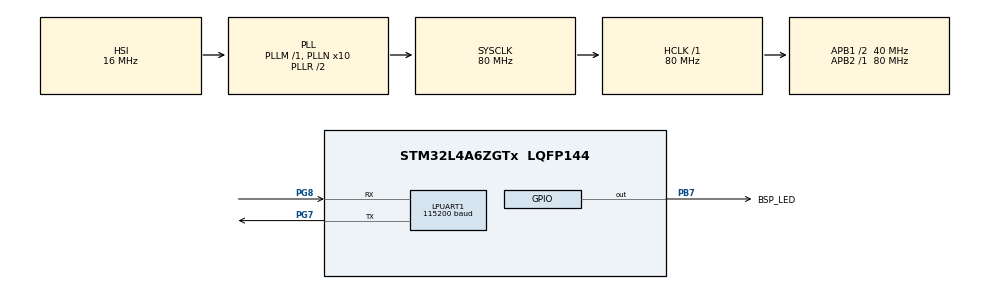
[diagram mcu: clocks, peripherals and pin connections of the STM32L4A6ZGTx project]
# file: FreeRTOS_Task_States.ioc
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FREERTOS.Tasks01=Default_Task,24,128,Start_Default_Task,Default,NULL,Dynamic,NULL,NULL;Task_2,8,128,Start_Task_2,Default,NULL,Dynamic,NULL,NULL
FREERTOS.configUSE_NEWLIB_REENTRANT=1
LPUART1.BaudRate=115200
LPUART1.WordLength=UART_WORDLENGTH_8B
Mcu.Family=STM32L4
Mcu.Name=STM32L4A6ZGTx
Mcu.Package=LQFP144
NVIC.PriorityGroup=NVIC_PRIORITYGROUP_4
NVIC.TIM6_DAC_IRQn=true\:15\:0\:false\:false\:true\:false\:false\:true\:true
NVIC.TimeBase=TIM6_DAC_IRQn
NVIC.TimeBaseIP=TIM6
PA13\ (JTMS/SWDIO).Mode=Serial_Wire
PA13\ (JTMS/SWDIO).Signal=SYS_JTMS-SWDIO
PA14\ (JTCK/SWCLK).Mode=Serial_Wire
PA14\ (JTCK/SWCLK).Signal=SYS_JTCK-SWCLK
PB7.GPIO_Label=BSP_LED
PB7.Signal=GPIO_Output
PG7.Mode=Asynchronous
PG7.Signal=LPUART1_TX
PG8.Mode=Asynchronous
PG8.Signal=LPUART1_RX
ProjectManager.HeapSize=0x200
ProjectManager.StackSize=0x400
ProjectManager.TargetToolchain=STM32CubeIDE
RCC.ADCFreq_Value=192000000
RCC.AHBFreq_Value=80000000
RCC.APB1CLKDivider=RCC_HCLK_DIV2
RCC.APB1Freq_Value=40000000
RCC.APB1TimFreq_Value=80000000
RCC.APB2Freq_Value=80000000
RCC.APB2TimFreq_Value=80000000
RCC.CortexFreq_Value=80000000
RCC.FLatency=FLASH_LATENCY_4
RCC.HCLKFreq_Value=80000000
RCC.HSE_VALUE=8000000
RCC.HSI48_VALUE=48000000
RCC.HSI_VALUE=16000000
RCC.MSI_VALUE=4000000
RCC.PLLN=10
RCC.PLLSAI1N=24
RCC.PLLSourceVirtual=RCC_PLLSOURCE_HSI
RCC.SYSCLKFreq_VALUE=80000000
RCC.SYSCLKSource=RCC_SYSCLKSOURCE_PLLCLK
RCC.USBFreq_Value=192000000
RCC.VCOOutputFreq_Value=160000000
VP_FREERTOS_VS_CMSIS_V2.Mode=CMSIS_V2
VP_SYS_VS_tim6.Mode=TIM6
board=NUCLEO-L4A6ZG

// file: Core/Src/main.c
/* USER CODE BEGIN Header */
/**
  ******************************************************************************
  * @file           : main.c
  * @brief          : Main program body
  ******************************************************************************
  * @attention
  *
  * Copyright (c) 2024 STMicroelectronics.
  * All rights reserved.
  *
  * This software is licensed under terms that can be found in the LICENSE file
  * in the root directory of this software component.
  * If no LICENSE file comes with this software, it is provided AS-IS.
  *
  ******************************************************************************
  */
/* USER CODE END Header */
#include "main.h"
#include "cmsis_os.h"

/* USER CODE BEGIN Includes */
#include <stdio.h>
/* USER CODE END Includes */

UART_HandleTypeDef hlpuart1;

/* Definitions for Default_Task */
osThreadId_t Default_TaskHandle;
const osThreadAttr_t Default_Task_attributes = {
  .name = "Default_Task",
  .stack_size = 128 * 4,
  .priority = (osPriority_t) osPriorityNormal,
};
/* Definitions for Task_2 */
osThreadId_t Task_2Handle;
const osThreadAttr_t Task_2_attributes = {
  .name = "Task_2",
  .stack_size = 128 * 4,
  .priority = (osPriority_t) osPriorityLow,
};

/* Defination for Idle Task */
osThreadId_t Idle_TaskHandle;
const osThreadAttr_t Idle_Task_attributes = {
	.name = "Idle_Task",
	.stack_size = 128 * 4,
	.priority = (osPriority_t) osPriorityIdle,
};

/* USER CODE BEGIN PV */
uint8_t count = 0;
/* USER CODE END PV */

void SystemClock_Config(void);
static void MX_GPIO_Init(void);
static void MX_LPUART1_UART_Init(void);
void Start_Default_Task(void *argument);
void Start_Task_2(void *argument);
void Start_Idle_Task(void *argument);

int main(void)
{

  /* MCU Configuration--------------------------------------------------------*/

  /* Reset of all peripherals, Initializes the Flash interface and the Systick. */
  HAL_Init();

  /* Configure the system clock */
  SystemClock_Config();

  /* Initialize all configured peripherals */
  MX_GPIO_Init();
  MX_LPUART1_UART_Init();

  /* Init scheduler */
  osKernelInitialize();

  /* Create the thread(s) */
  /* creation of Default_Task */
  Default_TaskHandle = osThreadNew(Start_Default_Task, NULL, &Default_Task_attributes);
  if(Default_TaskHandle == NULL)
  {
	  printf("Failed to create Default Task\r\n");
  }

  /* creation of Task_2 */
  Task_2Handle = osThreadNew(Start_Task_2, NULL, &Task_2_attributes);
  if(Task_2Handle == NULL)
  {
	  printf("Failed to create Task- 2\r\n");
  }
  /* USER CODE BEGIN RTOS_THREADS */
  /* add threads, ... */
  /* creation of Idle Task */
  Idle_TaskHandle = osThreadNew(Start_Idle_Task, NULL, &Idle_Task_attributes);
  if(Idle_TaskHandle == NULL)
  {
	  printf("Failed to create Idle Task\r\n");
  }
  /* USER CODE END RTOS_THREADS */

  /* Start scheduler */
  osKernelStart();

  /* We should never get here as control is now taken by the scheduler */
  /* Infinite loop */
  while (1)
  {

  }
}

void SystemClock_Config(void)
{
  RCC_OscInitTypeDef RCC_OscInitStruct = {0};
  RCC_ClkInitTypeDef RCC_ClkInitStruct = {0};

  /** Configure the main internal regulator output voltage
  */
  if (HAL_PWREx_ControlVoltageScaling(PWR_REGULATOR_VOLTAGE_SCALE1) != HAL_OK)
  {
    Error_Handler();
  }

  /** Initializes the RCC Oscillators according to the specified parameters
  * in the RCC_OscInitTypeDef structure.
  */
  RCC_OscInitStruct.OscillatorType = RCC_OSCILLATORTYPE_HSI;
  RCC_OscInitStruct.HSIState = RCC_HSI_ON;
  RCC_OscInitStruct.HSICalibrationValue = RCC_HSICALIBRATION_DEFAULT;
  RCC_OscInitStruct.PLL.PLLState = RCC_PLL_ON;
  RCC_OscInitStruct.PLL.PLLSource = RCC_PLLSOURCE_HSI;
  RCC_OscInitStruct.PLL.PLLM = 1;
  RCC_OscInitStruct.PLL.PLLN = 10;
  RCC_OscInitStruct.PLL.PLLP = RCC_PLLP_DIV2;
  RCC_OscInitStruct.PLL.PLLQ = RCC_PLLQ_DIV2;
  RCC_OscInitStruct.PLL.PLLR = RCC_PLLR_DIV2;
  if (HAL_RCC_OscConfig(&RCC_OscInitStruct) != HAL_OK)
  {
    Error_Handler();
  }

  /** Initializes the CPU, AHB and APB buses clocks
  */
  RCC_ClkInitStruct.ClockType = RCC_CLOCKTYPE_HCLK|RCC_CLOCKTYPE_SYSCLK
                              |RCC_CLOCKTYPE_PCLK1|RCC_CLOCKTYPE_PCLK2;
  RCC_ClkInitStruct.SYSCLKSource = RCC_SYSCLKSOURCE_PLLCLK;
  RCC_ClkInitStruct.AHBCLKDivider = RCC_SYSCLK_DIV1;
  RCC_ClkInitStruct.APB1CLKDivider = RCC_HCLK_DIV2;
  RCC_ClkInitStruct.APB2CLKDivider = RCC_HCLK_DIV1;

  if (HAL_RCC_ClockConfig(&RCC_ClkInitStruct, FLASH_LATENCY_4) != HAL_OK)
  {
    Error_Handler();
  }
}

static void MX_LPUART1_UART_Init(void)
{

  hlpuart1.Instance = LPUART1;
  hlpuart1.Init.BaudRate = 115200;
  hlpuart1.Init.WordLength = UART_WORDLENGTH_8B;
  hlpuart1.Init.StopBits = UART_STOPBITS_1;
  hlpuart1.Init.Parity = UART_PARITY_NONE;
  hlpuart1.Init.Mode = UART_MODE_TX_RX;
  hlpuart1.Init.HwFlowCtl = UART_HWCONTROL_NONE;
  hlpuart1.Init.OneBitSampling = UART_ONE_BIT_SAMPLE_DISABLE;
  hlpuart1.AdvancedInit.AdvFeatureInit = UART_ADVFEATURE_NO_INIT;
  if (HAL_UART_Init(&hlpuart1) != HAL_OK)
  {
    Error_Handler();
  }

}

static void MX_GPIO_Init(void)
{
  GPIO_InitTypeDef GPIO_InitStruct = {0};

  /* GPIO Ports Clock Enable */
  __HAL_RCC_GPIOG_CLK_ENABLE();
  HAL_PWREx_EnableVddIO2();
  __HAL_RCC_GPIOA_CLK_ENABLE();
  __HAL_RCC_GPIOB_CLK_ENABLE();

  /*Configure GPIO pin Output Level */
  HAL_GPIO_WritePin(BSP_LED_GPIO_Port, BSP_LED_Pin, GPIO_PIN_RESET);

  /*Configure GPIO pin : BSP_LED_Pin */
  GPIO_InitStruct.Pin = BSP_LED_Pin;
  GPIO_InitStruct.Mode = GPIO_MODE_OUTPUT_PP;
  GPIO_InitStruct.Pull = GPIO_NOPULL;
  GPIO_InitStruct.Speed = GPIO_SPEED_FREQ_LOW;
  HAL_GPIO_Init(BSP_LED_GPIO_Port, &GPIO_InitStruct);

}

void Start_Default_Task(void *argument)
{
  /* USER CODE BEGIN 5 */
  /* Infinite loop */
  for(;;)
  {
	printf("Hello from Default Task\r\n");
    osDelay(1000);
  }
  /* USER CODE END 5 */
}

void Start_Task_2(void *argument)
{
  /* USER CODE BEGIN Start_Task_2 */
  /* Infinite loop */
  for(;;)
  {

	printf("Hello from Task-2\r\r ------> count = %d\r\n", ++count);
    osDelay(1000);

    if(count == 5)
    {
    	printf("\r\nSuspend Default Task\r\n");
    	osThreadSuspend(Default_TaskHandle);
    }

    if(count == 10)
    {
    	printf("\r\nResume Default Task\r\n");
    	osThreadResume(Default_TaskHandle);
    }

    if(count == 15)
    {
    	printf("\r\nTerminate Default Task\r\n");
    	osThreadTerminate(Default_TaskHandle);

    }

    if(count == 20)
    {
    	printf("\r\nTerminate Task-2 & Continue to execute Idle Task\r\n");
    	osThreadTerminate(Task_2Handle);
//    	osThreadTerminate(NULL);    // it terminates the current execution
    }
  }
  /* USER CODE END Start_Task_2 */
}

void Start_Idle_Task(void *argument)
{
  /* USER CODE BEGIN Start_Task_2 */
  /* Infinite loop */
  for(;;)
  {
    HAL_GPIO_TogglePin(GPIOB, GPIO_PIN_7);
    osDelay(500);
  }
  /* USER CODE END Start_Task_2 */
}

void HAL_TIM_PeriodElapsedCallback(TIM_HandleTypeDef *htim)
{
  if (htim->Instance == TIM6) {
    HAL_IncTick();
  }
}

void Error_Handler(void)
{
  __disable_irq();
  while (1)
  {
  }
}
